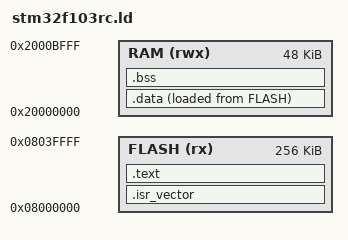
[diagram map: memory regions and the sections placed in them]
/* STM32F103RCT6: 256K flash, 48K SRAM.
 * Linked at the reset vector address -- no bootloader in front, the chip is
 * flashed straight over SWD. */
MEMORY
{
  FLASH (rx)  : ORIGIN = 0x08000000, LENGTH = 256K
  RAM   (rwx) : ORIGIN = 0x20000000, LENGTH = 48K
}

_estack = ORIGIN(RAM) + LENGTH(RAM);

ENTRY(Reset_Handler)

SECTIONS
{
  .isr_vector : { KEEP(*(.isr_vector)) } > FLASH

  .text :
  {
    *(.text*)
    *(.rodata*)
    . = ALIGN(4);
  } > FLASH

  /* Where the initialised data lives in flash, copied to RAM at reset. */
  _sidata = LOADADDR(.data);

  .data :
  {
    . = ALIGN(4);
    _sdata = .;
    *(.data*)
    . = ALIGN(4);
    _edata = .;
  } > RAM AT > FLASH

  .bss :
  {
    . = ALIGN(4);
    _sbss = .;
    *(.bss*)
    *(COMMON)
    . = ALIGN(4);
    _ebss = .;
  } > RAM

  /DISCARD/ : { *(.ARM.exidx*) *(.note*) *(.comment) }
}
